# STM32F373C8T6 register map
File version: 1.0
Registers are 32-bit, access not given, reset 0x0 unless marked. A register's access mark holds for its fields unless they carry their own. Offsets are from the block's base; [hi:lo] are bit positions; {n}, {i} and the like mark numbered series.

## DAC1
Base 0x40007400
Same registers: DAC2 0x40009800
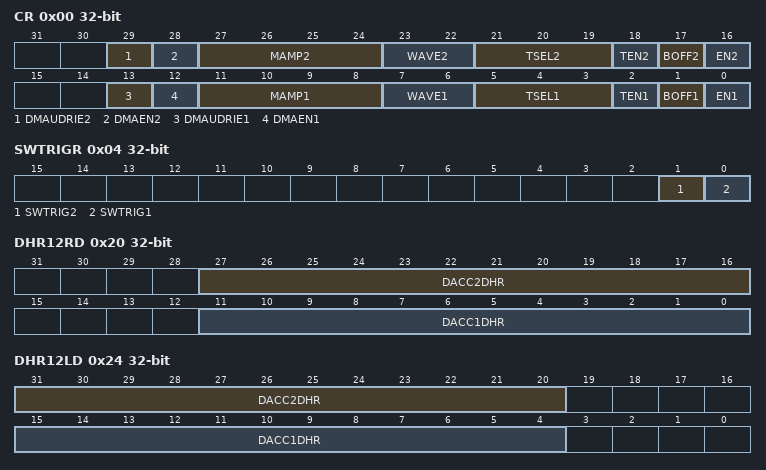
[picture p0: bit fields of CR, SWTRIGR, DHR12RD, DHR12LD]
0x00 CR
  [29] DMAUDRIE2, [28] DMAEN2, [27:24] MAMP2, [23:22] WAVE2, [21:19] TSEL2, [18] TEN2, [17] BOFF2, [16] EN2, [13] DMAUDRIE1, [12] DMAEN1, [11:8] MAMP1, [7:6] WAVE1, [5:3] TSEL1, [2] TEN1, [1] BOFF1, [0] EN1
0x04 SWTRIGR
  [1] SWTRIG2, [0] SWTRIG1
0x08 DHR12R1
  [11:0] DACC1DHR
0x0C DHR12L1
  [15:4] DACC1DHR
0x10 DHR8R1
  [7:0] DACC1DHR
0x14 DHR12R2
  [11:0] DACC2DHR
0x18 DHR12L2
  [15:4] DACC2DHR
0x1C DHR8R2
  [7:0] DACC2DHR
0x20 DHR12RD
  [27:16] DACC2DHR, [11:0] DACC1DHR
0x24 DHR12LD
  [31:20] DACC2DHR, [15:4] DACC1DHR
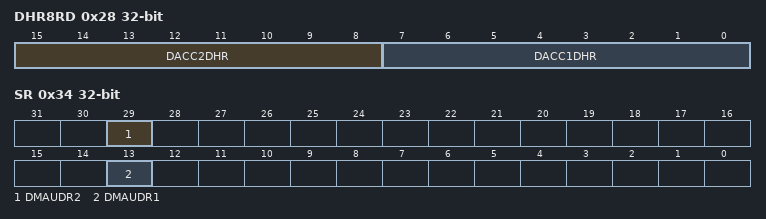
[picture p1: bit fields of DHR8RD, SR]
0x28 DHR8RD
  [15:8] DACC2DHR, [7:0] DACC1DHR
0x2C DOR1
  [11:0] DACC1DOR
0x30 DOR2
  [11:0] DACC2DOR
0x34 SR
  [29] DMAUDR2, [13] DMAUDR1

## CEC
Base 0x40007800
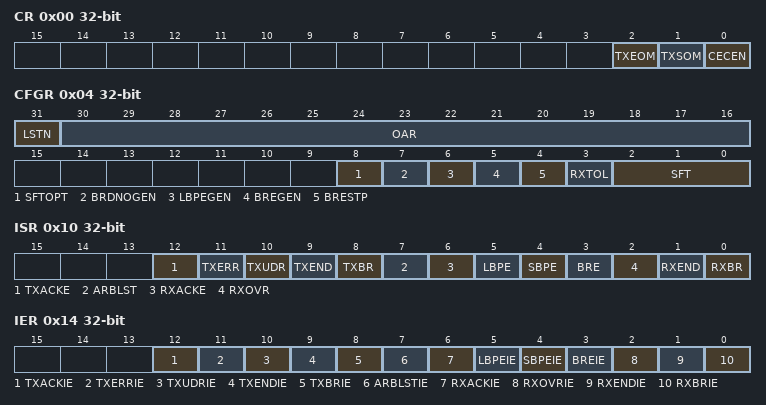
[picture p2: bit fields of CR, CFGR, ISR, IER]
0x00 CR
  [2] TXEOM, [1] TXSOM, [0] CECEN
0x04 CFGR
  [31] LSTN, [30:16] OAR, [8] SFTOPT, [7] BRDNOGEN, [6] LBPEGEN, [5] BREGEN, [4] BRESTP, [3] RXTOL, [2:0] SFT
0x08 TXDR
  [7:0] TXD
0x0C RXDR
  [7:0] RXD
0x10 ISR
  [12] TXACKE, [11] TXERR, [10] TXUDR, [9] TXEND, [8] TXBR, [7] ARBLST, [6] RXACKE, [5] LBPE, [4] SBPE, [3] BRE, [2] RXOVR, [1] RXEND, [0] RXBR
0x14 IER
  [12] TXACKIE, [11] TXERRIE, [10] TXUDRIE, [9] TXENDIE, [8] TXBRIE, [7] ARBLSTIE, [6] RXACKIE, [5] LBPEIE, [4] SBPEIE, [3] BREIE, [2] RXOVRIE, [1] RXENDIE, [0] RXBRIE

## COMP
Base 0x40010000
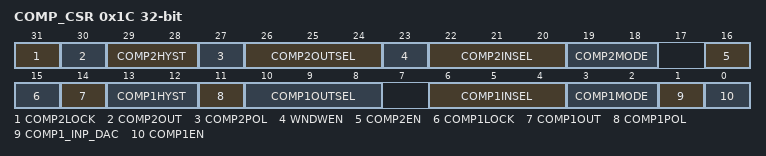
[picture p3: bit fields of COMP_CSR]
0x1C COMP_CSR
  [31] COMP2LOCK, [30] COMP2OUT, [29:28] COMP2HYST, [27] COMP2POL, [26:24] COMP2OUTSEL, [23] WNDWEN, [22:20] COMP2INSEL, [19:18] COMP2MODE, [16] COMP2EN, [15] COMP1LOCK, [14] COMP1OUT, [13:12] COMP1HYST, [11] COMP1POL, [10:8] COMP1OUTSEL, [6:4] COMP1INSEL, [3:2] COMP1MODE, [1] COMP1_INP_DAC, [0] COMP1EN

## SYSCFG
Base 0x40010000
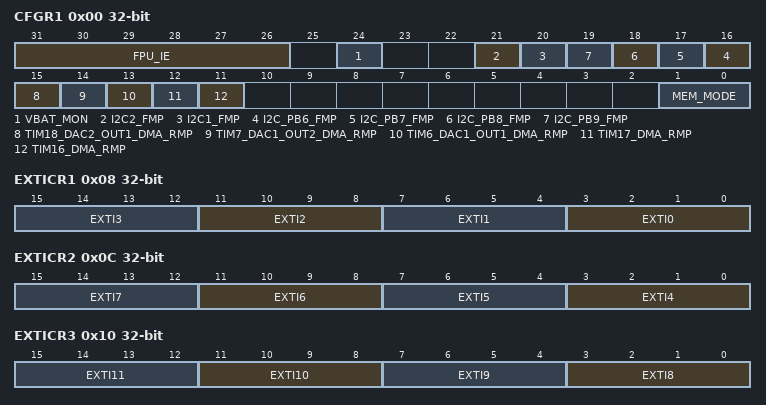
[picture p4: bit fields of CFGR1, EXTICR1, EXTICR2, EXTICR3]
0x00 CFGR1
  [31:26] FPU_IE, [24] VBAT_MON, [21] I2C2_FMP, [20] I2C1_FMP, [n+10] I2C_PB{n}_FMP (n=6..9), [15] TIM18_DAC2_OUT1_DMA_RMP, [14] TIM7_DAC1_OUT2_DMA_RMP, [13] TIM6_DAC1_OUT1_DMA_RMP, [12] TIM17_DMA_RMP, [11] TIM16_DMA_RMP, [1:0] MEM_MODE
0x08 EXTICR1
  [4n+3:4n] EXTI{n} (n=0..3)
0x0C EXTICR2
  [4n-13:4n-16] EXTI{n} (n=4..7)
0x10 EXTICR3
  [4n-29:4n-32] EXTI{n} (n=8..11)
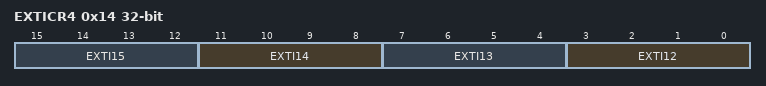
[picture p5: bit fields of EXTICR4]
0x14 EXTICR4
  [4n-45:4n-48] EXTI{n} (n=12..15)
0x18 CFGR2

## EXTI
Base 0x40010400
0x00 IMR
  [28:0] MR
0x04 EMR
  [28:0] MR
0x08 RTSR
  [22:0] TR
0x0C FTSR
  [22:0] TR
0x10 SWIER
  [22:0] SWIER
0x14 PR
  [22:0] PR

## ADC
Base 0x40012400
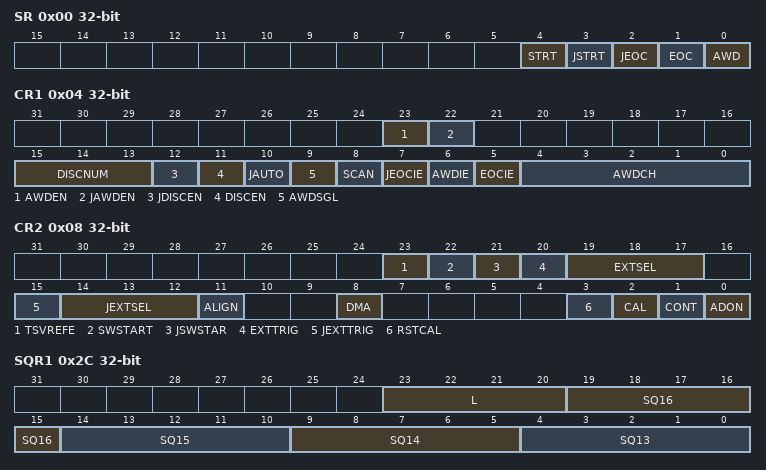
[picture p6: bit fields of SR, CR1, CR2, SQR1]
0x00 SR
  [4] STRT, [3] JSTRT, [2] JEOC, [1] EOC, [0] AWD
0x04 CR1
  [23] AWDEN, [22] JAWDEN, [15:13] DISCNUM, [12] JDISCEN, [11] DISCEN, [10] JAUTO, [9] AWDSGL, [8] SCAN, [7] JEOCIE, [6] AWDIE, [5] EOCIE, [4:0] AWDCH
0x08 CR2
  [23] TSVREFE, [22] SWSTART, [21] JSWSTAR, [20] EXTTRIG, [19:17] EXTSEL, [15] JEXTTRIG, [14:12] JEXTSEL, [11] ALIGN, [8] DMA, [3] RSTCAL, [2] CAL, [1] CONT, [0] ADON
0x0C SMPR1
  [31:0] SMP
0x10 SMPR2
  [31:0] SMP
{0x10+4i} JOFR{i} (i=1..4)
  [11:0] JOFFSET{i}
0x24 HTR
  [11:0] HT
0x28 LTR
  [11:0] LT
0x2C SQR1
  [23:20] L, [5n-61:5n-65] SQ{n} (n=13..16)
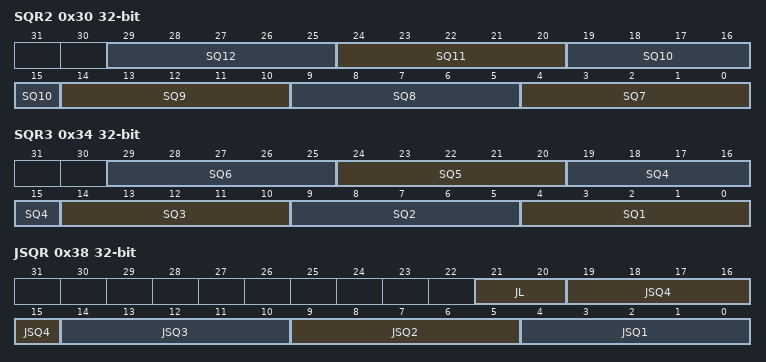
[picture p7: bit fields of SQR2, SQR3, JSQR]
0x30 SQR2
  [5n-31:5n-35] SQ{n} (n=7..12)
0x34 SQR3
  [5n-1:5n-5] SQ{n} (n=1..6)
0x38 JSQR
  [21:20] JL, [5n-1:5n-5] JSQ{n} (n=1..4)
{0x38+4i} JDR{i} (i=1..4)
  [15:0] JDATA
0x4C DR
  [15:0] DATA

## TIM15
Base 0x40014000
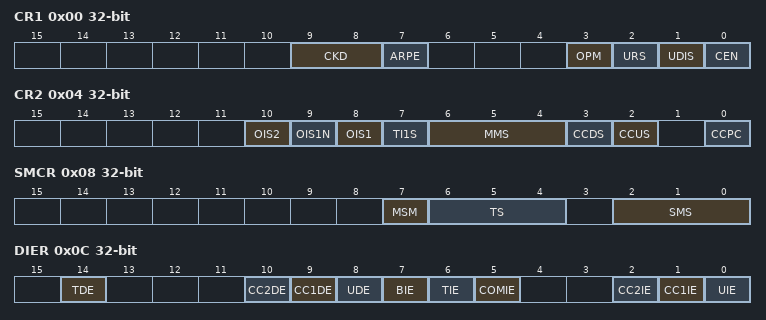
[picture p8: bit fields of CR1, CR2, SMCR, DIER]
0x00 CR1
  [9:8] CKD, [7] ARPE, [3] OPM, [2] URS, [1] UDIS, [0] CEN
0x04 CR2
  [10] OIS2, [9] OIS1N, [8] OIS1, [7] TI1S, [6:4] MMS, [3] CCDS, [2] CCUS, [0] CCPC
0x08 SMCR
  [7] MSM, [6:4] TS, [2:0] SMS
0x0C DIER
  [14] TDE, [10] CC2DE, [9] CC1DE, [8] UDE, [7] BIE, [6] TIE, [5] COMIE, [2] CC2IE, [1] CC1IE, [0] UIE
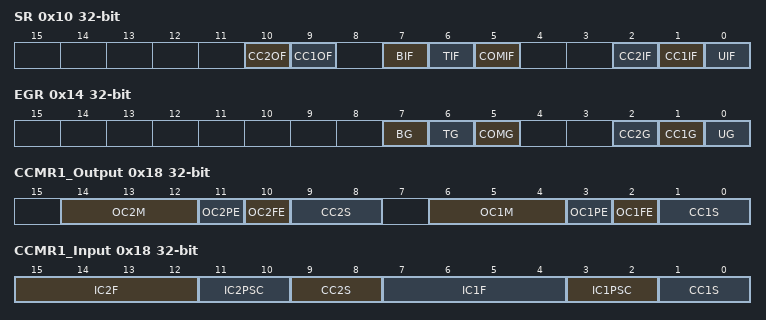
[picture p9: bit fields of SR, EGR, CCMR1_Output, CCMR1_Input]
0x10 SR
  [10] CC2OF, [9] CC1OF, [7] BIF, [6] TIF, [5] COMIF, [2] CC2IF, [1] CC1IF, [0] UIF
0x14 EGR
  [7] BG, [6] TG, [5] COMG, [2] CC2G, [1] CC1G, [0] UG
0x18 CCMR1_Output
  [14:12] OC2M, [11] OC2PE, [10] OC2FE, [9:8] CC2S, [6:4] OC1M, [3] OC1PE, [2] OC1FE, [1:0] CC1S
0x18 CCMR1_Input
  [15:12] IC2F, [11:10] IC2PSC, [9:8] CC2S, [7:4] IC1F, [3:2] IC1PSC, [1:0] CC1S
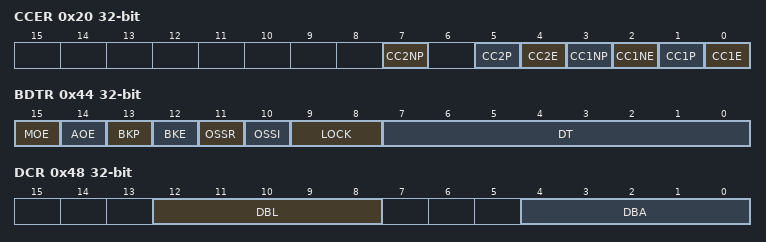
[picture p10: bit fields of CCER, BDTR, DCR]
0x20 CCER
  [7] CC2NP, [5] CC2P, [4] CC2E, [3] CC1NP, [2] CC1NE, [1] CC1P, [0] CC1E
0x24 CNT
  [15:0] CNT
0x28 PSC
  [15:0] PSC
0x2C ARR
  [15:0] ARR
0x30 RCR
  [7:0] REP
0x34 CCR1
  [15:0] CCR1
0x38 CCR2
  [15:0] CCR2
0x44 BDTR
  [15] MOE, [14] AOE, [13] BKP, [12] BKE, [11] OSSR, [10] OSSI, [9:8] LOCK, [7:0] DT
0x48 DCR
  [12:8] DBL, [4:0] DBA
0x4C DMAR
  [15:0] DMAB
